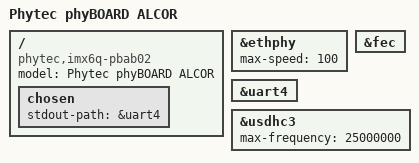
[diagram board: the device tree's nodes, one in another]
/*
 * Copyright 2014 Christian Hemp <c.hemp@phytec.de>, PHYTEC Messtechnik GmbH
 *
 * The code contained herein is licensed under the GNU General Public
 * License. You may obtain a copy of the GNU General Public License
 * Version 2 or later at the following locations:
 *
 * http://www.opensource.org/licenses/gpl-license.html
 * http://www.gnu.org/copyleft/gpl.html
 */

/dts-v1/;
#include "imx6q-phytec-pfla02.dtsi"

/ {
	model = "Phytec phyBOARD ALCOR";
	compatible = "phytec,imx6q-pbab02", "phytec,imx6q-pfla02", "fsl,imx6q";

	chosen {
		stdout-path = &uart4;
	};
};

&ethphy {
	max-speed = <100>;
};

&fec {
	status = "okay";
};

&uart4 {
	status = "okay";
};

&usdhc3 {
	status = "okay";
	max-frequency = <25000000>; /* 25 Mhz */
};
